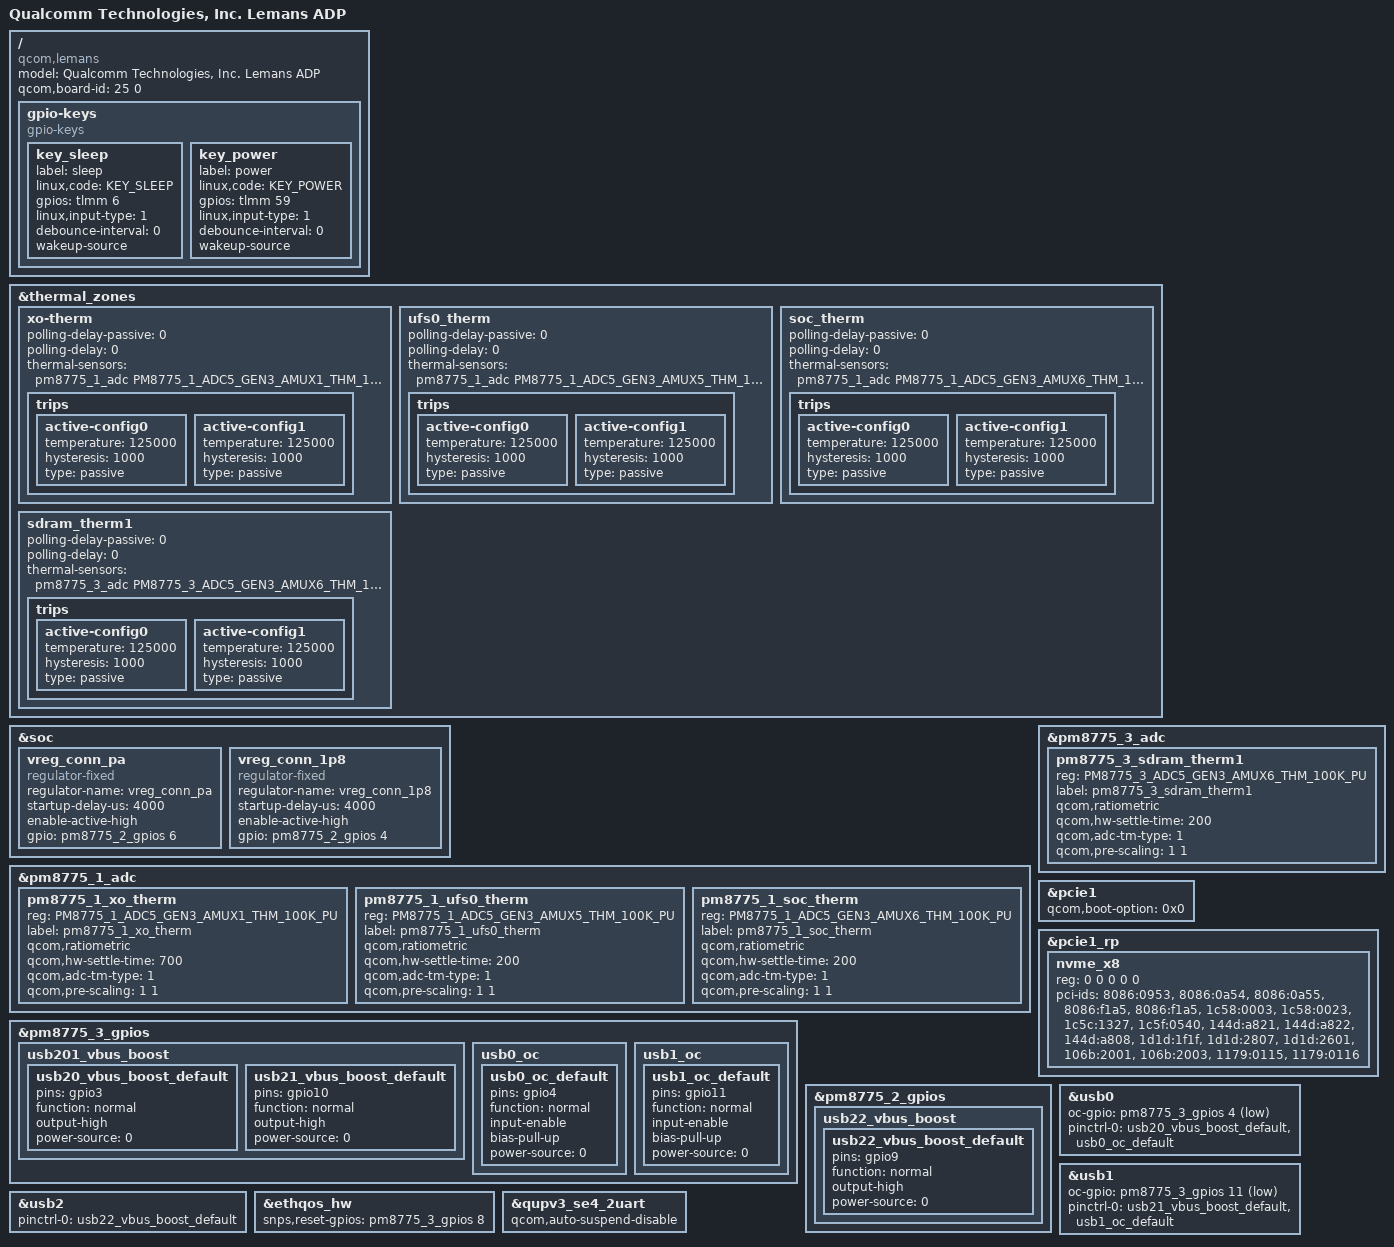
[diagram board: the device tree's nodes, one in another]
#include "lemans-pmic-overlay.dtsi"
#include <dt-bindings/gpio/gpio.h>
#include "lemans-thermal-overlay.dtsi"

/ {
	model = "Qualcomm Technologies, Inc. Lemans ADP";
	compatible =  "qcom,lemans", "qcom,adp";
	qcom,board-id = <25 0>;

	gpio-keys {
		compatible = "gpio-keys";

		key_sleep {
			label = "sleep";
			linux,code = <KEY_SLEEP>;
			gpios = <&tlmm 6 GPIO_ACTIVE_HIGH>;
			linux,input-type = <1>;
			debounce-interval = <0>;
			wakeup-source;
		};

		key_power {
			label = "power";
			linux,code = <KEY_POWER>;
			gpios = <&tlmm 59 GPIO_ACTIVE_HIGH>;
			linux,input-type = <1>;
			debounce-interval = <0>;
			wakeup-source;
		};
	};
};

&thermal_zones {
	xo-therm {
		polling-delay-passive = <0>;
		polling-delay = <0>;
		thermal-sensors = <&pm8775_1_adc PM8775_1_ADC5_GEN3_AMUX1_THM_100K_PU>;
		trips {
			active-config0 {
				temperature = <125000>;
				hysteresis = <1000>;
				type = "passive";
			};

			active-config1 {
				temperature = <125000>;
				hysteresis = <1000>;
				type = "passive";
			};
		};
	};

	ufs0_therm {
		polling-delay-passive = <0>;
		polling-delay = <0>;
		thermal-sensors = <&pm8775_1_adc PM8775_1_ADC5_GEN3_AMUX5_THM_100K_PU>;
		trips {
			active-config0 {
				temperature = <125000>;
				hysteresis = <1000>;
				type = "passive";
			};

			active-config1 {
				temperature = <125000>;
				hysteresis = <1000>;
				type = "passive";
			};
		};
	};

	soc_therm {
		polling-delay-passive = <0>;
		polling-delay = <0>;
		thermal-sensors = <&pm8775_1_adc PM8775_1_ADC5_GEN3_AMUX6_THM_100K_PU>;
		trips {
			active-config0 {
				temperature = <125000>;
				hysteresis = <1000>;
				type = "passive";
			};

			active-config1 {
				temperature = <125000>;
				hysteresis = <1000>;
				type = "passive";
			};
		};
	};

	sdram_therm1 {
		polling-delay-passive = <0>;
		polling-delay = <0>;
		thermal-sensors = <&pm8775_3_adc PM8775_3_ADC5_GEN3_AMUX6_THM_100K_PU>;
		trips {
			active-config0 {
			temperature = <125000>;
			hysteresis = <1000>;
			type = "passive";
			};

			active-config1 {
				temperature = <125000>;
				hysteresis = <1000>;
				type = "passive";
			};
		};
	};
};

&soc {
	/* PWR_CTR1_VDD_PA supply */
	vreg_conn_pa: vreg_conn_pa {
		compatible = "regulator-fixed";
		regulator-name = "vreg_conn_pa";
		startup-delay-us = <4000>;
		enable-active-high;
		gpio = <&pm8775_2_gpios 6 0>;
	};

	/* PWR_CTR2_VDD_1P8 supply */
	vreg_conn_1p8: vreg_conn_1p8 {
		compatible = "regulator-fixed";
		regulator-name = "vreg_conn_1p8";
		startup-delay-us = <4000>;
		enable-active-high;
		gpio = <&pm8775_2_gpios 4 0>;
	};

};

&pm8775_1_adc {
	pm8775_1_xo_therm {
		reg = <PM8775_1_ADC5_GEN3_AMUX1_THM_100K_PU>;
		label = "pm8775_1_xo_therm";
		qcom,ratiometric;
		qcom,hw-settle-time = <700>;
		qcom,adc-tm-type = <1>;
		qcom,pre-scaling = <1 1>;
	};

	pm8775_1_ufs0_therm {
		reg = <PM8775_1_ADC5_GEN3_AMUX5_THM_100K_PU>;
		label = "pm8775_1_ufs0_therm";
		qcom,ratiometric;
		qcom,hw-settle-time = <200>;
		qcom,adc-tm-type = <1>;
		qcom,pre-scaling = <1 1>;
	};

	pm8775_1_soc_therm {
		reg = <PM8775_1_ADC5_GEN3_AMUX6_THM_100K_PU>;
		label = "pm8775_1_soc_therm";
		qcom,ratiometric;
		qcom,hw-settle-time = <200>;
		qcom,adc-tm-type = <1>;
		qcom,pre-scaling = <1 1>;
	};
};

&pm8775_3_adc {
	pm8775_3_sdram_therm1 {
		reg = <PM8775_3_ADC5_GEN3_AMUX6_THM_100K_PU>;
		label = "pm8775_3_sdram_therm1";
		qcom,ratiometric;
		qcom,hw-settle-time = <200>;
		qcom,adc-tm-type = <1>;
		qcom,pre-scaling = <1 1>;
	};
};

&pcie1 {
	qcom,boot-option = <0x0>;
};

&pcie1_rp {
	nvme_x8 {
		reg = <0 0 0 0 0>;
		pci-ids =
			"8086:0953",
			"8086:0a54",
			"8086:0a55",
			"8086:f1a5",
			"8086:f1a5",
			"1c58:0003",
			"1c58:0023",
			"1c5c:1327",
			"1c5f:0540",
			"144d:a821",
			"144d:a822",
			"144d:a808",
			"1d1d:1f1f",
			"1d1d:2807",
			"1d1d:2601",
			"106b:2001",
			"106b:2003",
			"1179:0115",
			"1179:0116";
	};
};

&pm8775_3_gpios {
	usb201_vbus_boost {
		usb20_vbus_boost_default: usb20_vbus_boost_default {
			pins = "gpio3";
			function = "normal";
			output-high;
			power-source = <0>;
		};

		usb21_vbus_boost_default: usb21_vbus_boost_default {
			pins = "gpio10";
			function = "normal";
			output-high;
			power-source = <0>;
		};
	};

	usb0_oc {
		usb0_oc_default: usb0_oc_default {
			pins = "gpio4";
			function = "normal";
			input-enable;
			bias-pull-up;
			power-source = <0>;
		};
	};

	usb1_oc {
		usb1_oc_default: usb1_oc_default {
			pins = "gpio11";
			function = "normal";
			input-enable;
			bias-pull-up;
			power-source = <0>;
		};
	};
};

&pm8775_2_gpios {
	usb22_vbus_boost {
		usb22_vbus_boost_default: usb22_vbus_boost_default {
			pins = "gpio9";
			function = "normal";
			output-high;
			power-source = <0>;
		};
	};
};

&usb0 {
	oc-gpio = <&pm8775_3_gpios 4 1>;
	pinctrl-names = "default";
	pinctrl-0 = <&usb20_vbus_boost_default &usb0_oc_default>;
};

&usb1 {
	oc-gpio = <&pm8775_3_gpios 11 1>;
	pinctrl-names = "default";
	pinctrl-0 = <&usb21_vbus_boost_default &usb1_oc_default>;
};

&usb2 {
	pinctrl-names = "default";
	pinctrl-0 = <&usb22_vbus_boost_default>;
};

&ethqos_hw {
	snps,reset-gpios = <&pm8775_3_gpios 8 GPIO_ACTIVE_HIGH>;
};

&qupv3_se4_2uart {
	status = "ok";
	qcom,auto-suspend-disable;
};
